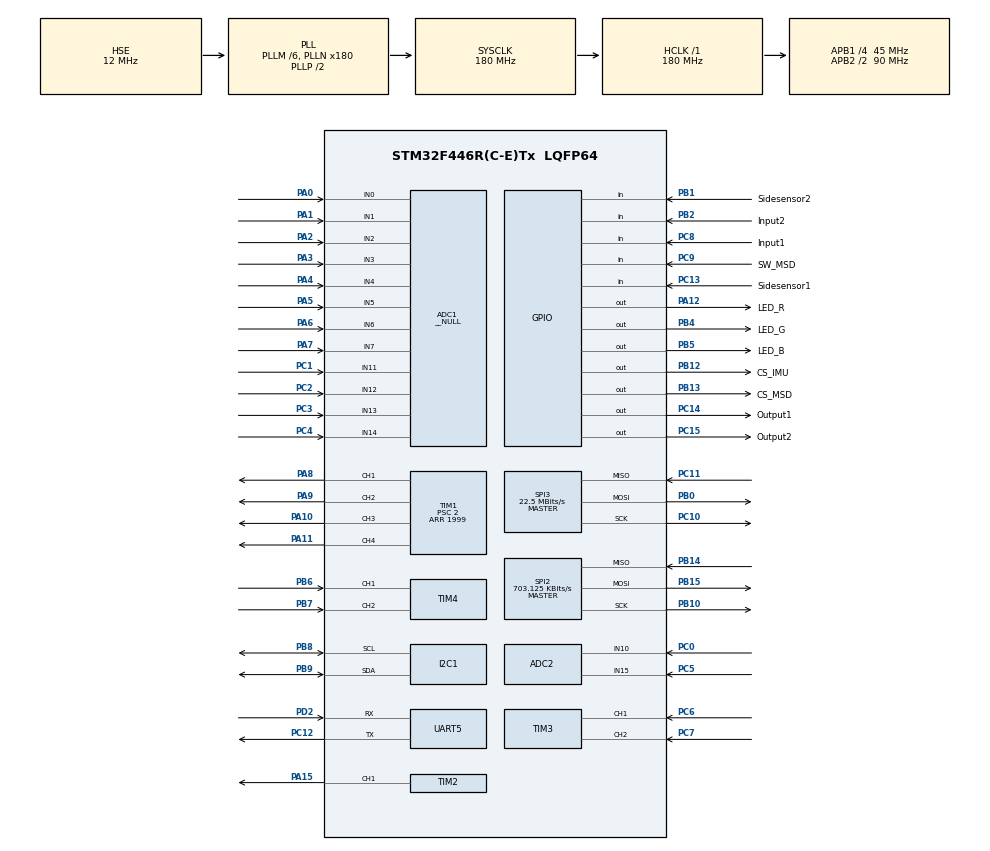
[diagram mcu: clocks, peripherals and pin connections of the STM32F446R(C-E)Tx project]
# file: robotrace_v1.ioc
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ADC1.Channel-1\#ChannelRegularConversion=ADC_CHANNEL_11
ADC1.Channel-10\#ChannelRegularConversion=ADC_CHANNEL_6
ADC1.Channel-11\#ChannelRegularConversion=ADC_CHANNEL_7
ADC1.Channel-12\#ChannelRegularConversion=ADC_CHANNEL_14
ADC1.Channel-2\#ChannelRegularConversion=ADC_CHANNEL_12
ADC1.Channel-3\#ChannelRegularConversion=ADC_CHANNEL_13
ADC1.Channel-4\#ChannelRegularConversion=ADC_CHANNEL_0
ADC1.Channel-5\#ChannelRegularConversion=ADC_CHANNEL_1
ADC1.Channel-6\#ChannelRegularConversion=ADC_CHANNEL_2
ADC1.Channel-7\#ChannelRegularConversion=ADC_CHANNEL_3
ADC1.Channel-8\#ChannelRegularConversion=ADC_CHANNEL_4
ADC1.Channel-9\#ChannelRegularConversion=ADC_CHANNEL_5
ADC1.ClockPrescaler=ADC_CLOCK_SYNC_PCLK_DIV4
ADC1.ContinuousConvMode=DISABLE
ADC1.DMAContinuousRequests=ENABLE
ADC1.DiscontinuousConvMode=DISABLE
ADC1.EOCSelection=ADC_EOC_SINGLE_CONV
ADC1.ExternalTrigConv=ADC_EXTERNALTRIGCONV_T2_TRGO
ADC1.ExternalTrigConvEdge=ADC_EXTERNALTRIGCONVEDGE_RISING
ADC1.InjNumberOfConversion=0
ADC1.Mode=__NULL
ADC1.NbrOfConversion=12
ADC1.NbrOfConversionFlag=1
ADC1.Rank-1\#ChannelRegularConversion=1
ADC1.Rank-10\#ChannelRegularConversion=10
ADC1.Rank-11\#ChannelRegularConversion=11
ADC1.Rank-12\#ChannelRegularConversion=12
ADC1.Rank-2\#ChannelRegularConversion=2
ADC1.Rank-3\#ChannelRegularConversion=3
ADC1.Rank-4\#ChannelRegularConversion=4
ADC1.Rank-5\#ChannelRegularConversion=5
ADC1.Rank-6\#ChannelRegularConversion=6
ADC1.Rank-7\#ChannelRegularConversion=7
ADC1.Rank-8\#ChannelRegularConversion=8
ADC1.Rank-9\#ChannelRegularConversion=9
ADC1.SamplingTime-1\#ChannelRegularConversion=ADC_SAMPLETIME_84CYCLES
ADC1.SamplingTime-10\#ChannelRegularConversion=ADC_SAMPLETIME_84CYCLES
ADC1.SamplingTime-11\#ChannelRegularConversion=ADC_SAMPLETIME_84CYCLES
ADC1.SamplingTime-12\#ChannelRegularConversion=ADC_SAMPLETIME_84CYCLES
ADC1.SamplingTime-2\#ChannelRegularConversion=ADC_SAMPLETIME_84CYCLES
ADC1.SamplingTime-3\#ChannelRegularConversion=ADC_SAMPLETIME_84CYCLES
ADC1.SamplingTime-4\#ChannelRegularConversion=ADC_SAMPLETIME_84CYCLES
ADC1.SamplingTime-5\#ChannelRegularConversion=ADC_SAMPLETIME_84CYCLES
ADC1.SamplingTime-6\#ChannelRegularConversion=ADC_SAMPLETIME_84CYCLES
ADC1.SamplingTime-7\#ChannelRegularConversion=ADC_SAMPLETIME_84CYCLES
ADC1.SamplingTime-8\#ChannelRegularConversion=ADC_SAMPLETIME_84CYCLES
ADC1.SamplingTime-9\#ChannelRegularConversion=ADC_SAMPLETIME_84CYCLES
ADC1.ScanConvMode=ENABLE
ADC1.master=1
ADC2.Channel-0\#ChannelRegularConversion=ADC_CHANNEL_10
ADC2.Channel-1\#ChannelRegularConversion=ADC_CHANNEL_15
ADC2.ContinuousConvMode=ENABLE
ADC2.EOCSelection=ADC_EOC_SINGLE_CONV
ADC2.NbrOfConversion=2
ADC2.NbrOfConversionFlag=1
ADC2.Rank-0\#ChannelRegularConversion=1
ADC2.Rank-1\#ChannelRegularConversion=2
ADC2.SamplingTime-0\#ChannelRegularConversion=ADC_SAMPLETIME_480CYCLES
ADC2.SamplingTime-1\#ChannelRegularConversion=ADC_SAMPLETIME_480CYCLES
ADC2.ScanConvMode=ENABLE
Dma.ADC1.0.Direction=DMA_PERIPH_TO_MEMORY
Dma.ADC1.0.FIFOMode=DMA_FIFOMODE_DISABLE
Dma.ADC1.0.Instance=DMA2_Stream0
Dma.ADC1.0.MemDataAlignment=DMA_MDATAALIGN_HALFWORD
Dma.ADC1.0.MemInc=DMA_MINC_ENABLE
Dma.ADC1.0.Mode=DMA_CIRCULAR
Dma.ADC1.0.PeriphDataAlignment=DMA_PDATAALIGN_HALFWORD
Dma.ADC1.0.PeriphInc=DMA_PINC_DISABLE
Dma.ADC1.0.Priority=DMA_PRIORITY_LOW
Dma.Request0=ADC1
I2C1.DutyCycle=I2C_DUTYCYCLE_2
I2C1.I2C_Mode=I2C_Fast
I2C1.NoStretchMode=I2C_NOSTRETCH_ENABLE
Mcu.Family=STM32F4
Mcu.Name=STM32F446R(C-E)Tx
Mcu.Package=LQFP64
NVIC.DMA2_Stream0_IRQn=true\:0\:0\:false\:false\:true\:false\:true\:true
NVIC.PriorityGroup=NVIC_PRIORITYGROUP_0
NVIC.TIM2_IRQn=true\:0\:0\:false\:false\:true\:true\:true\:true
NVIC.TIM6_DAC_IRQn=true\:0\:0\:false\:false\:true\:true\:true\:true
NVIC.TIM7_IRQn=true\:0\:0\:false\:false\:true\:true\:true\:true
PA0-WKUP.Signal=ADCx_IN0
PA1.Signal=ADCx_IN1
PA10.Signal=S_TIM1_CH3
PA11.Signal=S_TIM1_CH4
PA12.GPIO_Label=LED_R
PA12.GPIO_PuPd=GPIO_PULLUP
PA12.PinState=GPIO_PIN_SET
PA12.Signal=GPIO_Output
PA13.GPIO_Label=TMS
PA13.Mode=Trace_Asynchronous_SW
PA13.Signal=SYS_JTMS-SWDIO
PA14.GPIO_Label=TCK
PA14.Mode=Trace_Asynchronous_SW
PA14.Signal=SYS_JTCK-SWCLK
PA15.Signal=S_TIM2_CH1_ETR
PA2.Signal=ADCx_IN2
PA3.Signal=ADCx_IN3
PA4.Signal=ADCx_IN4
PA5.Signal=ADCx_IN5
PA6.Signal=ADCx_IN6
PA7.Signal=ADCx_IN7
PA8.Signal=S_TIM1_CH1
PA9.Signal=S_TIM1_CH2
PB0.Mode=Full_Duplex_Master
PB0.Signal=SPI3_MOSI
PB1.GPIO_Label=Sidesensor2
PB1.GPIO_PuPd=GPIO_PULLUP
PB1.Signal=GPIO_Input
PB10.Mode=Full_Duplex_Master
PB10.Signal=SPI2_SCK
PB12.GPIO_Label=CS_IMU
PB12.GPIO_PuPd=GPIO_PULLUP
PB12.PinState=GPIO_PIN_SET
PB12.Signal=GPIO_Output
PB13.GPIO_Label=CS_MSD
PB13.GPIO_PuPd=GPIO_PULLUP
PB13.PinState=GPIO_PIN_SET
PB13.Signal=GPIO_Output
PB14.Mode=Full_Duplex_Master
PB14.Signal=SPI2_MISO
PB15.Mode=Full_Duplex_Master
PB15.Signal=SPI2_MOSI
PB2.GPIO_Label=Input2
PB2.Signal=GPIO_Input
PB3.GPIO_Label=SWO
PB3.Mode=Trace_Asynchronous_SW
PB3.Signal=SYS_JTDO-SWO
PB4.GPIO_Label=LED_G
PB4.GPIO_PuPd=GPIO_PULLUP
PB4.PinState=GPIO_PIN_SET
PB4.Signal=GPIO_Output
PB5.GPIO_Label=LED_B
PB5.GPIO_PuPd=GPIO_PULLUP
PB5.PinState=GPIO_PIN_SET
PB5.Signal=GPIO_Output
PB6.Signal=S_TIM4_CH1
PB7.Signal=S_TIM4_CH2
PB8.Mode=I2C
PB8.Signal=I2C1_SCL
PB9.Mode=I2C
PB9.Signal=I2C1_SDA
PC0.Signal=ADCx_IN10
PC1.Signal=ADCx_IN11
PC10.Mode=Full_Duplex_Master
PC10.Signal=SPI3_SCK
PC11.Mode=Full_Duplex_Master
PC11.Signal=SPI3_MISO
PC12.Mode=Asynchronous
PC12.Signal=UART5_TX
PC13.GPIO_Label=Sidesensor1
PC13.GPIO_PuPd=GPIO_PULLUP
PC13.Signal=GPIO_Input
PC14-OSC32_IN.GPIO_Label=Output1
PC14-OSC32_IN.GPIO_PuPd=GPIO_PULLUP
PC14-OSC32_IN.Signal=GPIO_Output
PC15-OSC32_OUT.GPIO_Label=Output2
PC15-OSC32_OUT.GPIO_PuPd=GPIO_PULLUP
PC15-OSC32_OUT.Signal=GPIO_Output
PC2.Signal=ADCx_IN12
PC3.Signal=ADCx_IN13
PC4.Signal=ADCx_IN14
PC5.Signal=ADCx_IN15
PC6.Signal=S_TIM3_CH1
PC7.Signal=S_TIM3_CH2
PC8.GPIO_Label=Input1
PC8.GPIO_PuPd=GPIO_PULLUP
PC8.Signal=GPIO_Input
PC9.GPIO_Label=SW_MSD
PC9.GPIO_PuPd=GPIO_PULLUP
PC9.Signal=GPIO_Input
PD2.Mode=Asynchronous
PD2.Signal=UART5_RX
PH0-OSC_IN.Mode=HSE-External-Oscillator
PH0-OSC_IN.Signal=RCC_OSC_IN
PH1-OSC_OUT.Mode=HSE-External-Oscillator
PH1-OSC_OUT.Signal=RCC_OSC_OUT
ProjectManager.HeapSize=0x400
ProjectManager.StackSize=0x800
ProjectManager.TargetToolchain=STM32CubeIDE
RCC.48MHZClocksFreq_Value=84000000
RCC.AHBFreq_Value=180000000
RCC.APB1CLKDivider=RCC_HCLK_DIV4
RCC.APB1Freq_Value=45000000
RCC.APB1TimFreq_Value=90000000
RCC.APB2CLKDivider=RCC_HCLK_DIV2
RCC.APB2Freq_Value=90000000
RCC.APB2TimFreq_Value=180000000
RCC.CortexFreq_Value=180000000
RCC.FLatency-AdvancedSettings=FLASH_LATENCY_5
RCC.HCLKFreq_Value=180000000
RCC.HSE_VALUE=12000000
RCC.HSI_VALUE=16000000
RCC.PLLM=6
RCC.PLLN=180
RCC.PLLSourceVirtual=RCC_PLLSOURCE_HSE
RCC.SYSCLKFreq_VALUE=180000000
RCC.SYSCLKSource=RCC_SYSCLKSOURCE_PLLCLK
RCC.USBFreq_Value=180000000
RCC.VCOOutputFreq_Value=360000000
SH.ADCx_IN0.0=ADC1_IN0,IN0
SH.ADCx_IN1.0=ADC1_IN1,IN1
SH.ADCx_IN10.0=ADC2_IN10,IN10
SH.ADCx_IN11.0=ADC1_IN11,IN11
SH.ADCx_IN12.0=ADC1_IN12,IN12
SH.ADCx_IN13.0=ADC1_IN13,IN13
SH.ADCx_IN14.0=ADC1_IN14,IN14
SH.ADCx_IN15.0=ADC2_IN15,IN15
SH.ADCx_IN2.0=ADC1_IN2,IN2
SH.ADCx_IN3.0=ADC1_IN3,IN3
SH.ADCx_IN4.0=ADC1_IN4,IN4
SH.ADCx_IN5.0=ADC1_IN5,IN5
SH.ADCx_IN6.0=ADC1_IN6,IN6
SH.ADCx_IN7.0=ADC1_IN7,IN7
SH.S_TIM1_CH1.0=TIM1_CH1,PWM Generation1 CH1
SH.S_TIM1_CH2.0=TIM1_CH2,PWM Generation2 CH2
SH.S_TIM1_CH3.0=TIM1_CH3,PWM Generation3 CH3
SH.S_TIM1_CH4.0=TIM1_CH4,PWM Generation4 CH4
SH.S_TIM2_CH1_ETR.0=TIM2_CH1,PWM Generation1 CH1
SH.S_TIM3_CH1.0=TIM3_CH1,Encoder_Interface
SH.S_TIM3_CH2.0=TIM3_CH2,Encoder_Interface
SH.S_TIM4_CH1.0=TIM4_CH1,Encoder_Interface
SH.S_TIM4_CH2.0=TIM4_CH2,Encoder_Interface
SPI2.BaudRatePrescaler=SPI_BAUDRATEPRESCALER_64
SPI2.CLKPhase=SPI_PHASE_2EDGE
SPI2.CLKPolarity=SPI_POLARITY_HIGH
SPI2.CalculateBaudRate=703.125 KBits/s
SPI2.Direction=SPI_DIRECTION_2LINES
SPI2.FirstBit=SPI_FIRSTBIT_MSB
SPI2.Mode=SPI_MODE_MASTER
SPI2.VirtualType=VM_MASTER
SPI3.BaudRatePrescaler=SPI_BAUDRATEPRESCALER_2
SPI3.CalculateBaudRate=22.5 MBits/s
SPI3.Direction=SPI_DIRECTION_2LINES
SPI3.Mode=SPI_MODE_MASTER
SPI3.VirtualType=VM_MASTER
TIM1.Channel-PWM\ Generation1\ CH1=TIM_CHANNEL_1
TIM1.Channel-PWM\ Generation2\ CH2=TIM_CHANNEL_2
TIM1.Channel-PWM\ Generation3\ CH3=TIM_CHANNEL_3
TIM1.Channel-PWM\ Generation4\ CH4=TIM_CHANNEL_4
TIM1.OC3Preload_PWM=DISABLE
TIM1.OC4Preload_PWM=DISABLE
TIM1.Period=1999
TIM1.Prescaler=2
TIM2.AutoReloadPreload=TIM_AUTORELOAD_PRELOAD_DISABLE
TIM2.Channel-PWM\ Generation1\ CH1=TIM_CHANNEL_1
TIM2.CounterMode=TIM_COUNTERMODE_UP
TIM2.Period=1124
TIM2.Prescaler=11
TIM2.TIM_MasterOutputTrigger=TIM_TRGO_UPDATE
TIM3.EncoderMode=TIM_ENCODERMODE_TI12
TIM3.IC1Polarity=TIM_ICPOLARITY_RISING
TIM3.IC2Polarity=TIM_ICPOLARITY_FALLING
TIM4.EncoderMode=TIM_ENCODERMODE_TI12
TIM4.IC2Polarity=TIM_ICPOLARITY_RISING
TIM6.Period=7499
TIM6.Prescaler=11
TIM7.Period=749
TIM7.Prescaler=11
UART5.VirtualMode=Asynchronous
VP_FATFS_VS_Generic.Mode=User_defined
VP_TIM6_VS_ClockSourceINT.Mode=Enable_Timer
VP_TIM7_VS_ClockSourceINT.Mode=Enable_Timer
board=NUCLEO-F446RE

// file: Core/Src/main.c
/* USER CODE BEGIN Header */
/**
  ******************************************************************************
  * @file           : main.c
  * @brief          : Main program body
  ******************************************************************************
  * @attention
  *
  * Copyright (c) 2022 STMicroelectronics.
  * All rights reserved.
  *
  * This software is licensed under terms that can be found in the LICENSE file
  * in the root directory of this software component.
  * If no LICENSE file comes with this software, it is provided AS-IS.
  *
  ******************************************************************************
  */
/* USER CODE END Header */
#include "main.h"
#include "fatfs.h"

ADC_HandleTypeDef hadc1;
ADC_HandleTypeDef hadc2;
DMA_HandleTypeDef hdma_adc1;

I2C_HandleTypeDef hi2c1;

SPI_HandleTypeDef hspi2;
SPI_HandleTypeDef hspi3;

TIM_HandleTypeDef htim1;
TIM_HandleTypeDef htim2;
TIM_HandleTypeDef htim3;
TIM_HandleTypeDef htim4;
TIM_HandleTypeDef htim6;
TIM_HandleTypeDef htim7;

UART_HandleTypeDef huart5;

void SystemClock_Config(void);
static void MX_GPIO_Init(void);
static void MX_DMA_Init(void);
static void MX_ADC1_Init(void);
static void MX_I2C1_Init(void);
static void MX_SPI2_Init(void);
static void MX_TIM1_Init(void);
static void MX_TIM2_Init(void);
static void MX_UART5_Init(void);
static void MX_TIM3_Init(void);
static void MX_TIM4_Init(void);
static void MX_SPI3_Init(void);
static void MX_TIM6_Init(void);
static void MX_ADC2_Init(void);
static void MX_TIM7_Init(void);

int main(void)
{

  /* MCU Configuration--------------------------------------------------------*/

  /* Reset of all peripherals, Initializes the Flash interface and the Systick. */
  HAL_Init();

  /* Configure the system clock */
  SystemClock_Config();

  /* Initialize all configured peripherals */
  MX_GPIO_Init();
  MX_DMA_Init();
  MX_ADC1_Init();
  MX_I2C1_Init();
  MX_SPI2_Init();
  MX_TIM1_Init();
  MX_TIM2_Init();
  MX_UART5_Init();
  MX_TIM3_Init();
  MX_TIM4_Init();
  MX_SPI3_Init();
  MX_TIM6_Init();
  MX_ADC2_Init();
  MX_FATFS_Init();
  MX_TIM7_Init();
  /* USER CODE BEGIN 2 */
  initSystem();

  /* USER CODE END 2 */

  /* Infinite loop */
  /* USER CODE BEGIN WHILE */
  while (1)
  {
    loopSystem();
    /* USER CODE END WHILE */

  }
}

void SystemClock_Config(void)
{
  RCC_OscInitTypeDef RCC_OscInitStruct = {0};
  RCC_ClkInitTypeDef RCC_ClkInitStruct = {0};

  /** Configure the main internal regulator output voltage
  */
  __HAL_RCC_PWR_CLK_ENABLE();
  __HAL_PWR_VOLTAGESCALING_CONFIG(PWR_REGULATOR_VOLTAGE_SCALE1);

  /** Initializes the RCC Oscillators according to the specified parameters
  * in the RCC_OscInitTypeDef structure.
  */
  RCC_OscInitStruct.OscillatorType = RCC_OSCILLATORTYPE_HSE;
  RCC_OscInitStruct.HSEState = RCC_HSE_ON;
  RCC_OscInitStruct.PLL.PLLState = RCC_PLL_ON;
  RCC_OscInitStruct.PLL.PLLSource = RCC_PLLSOURCE_HSE;
  RCC_OscInitStruct.PLL.PLLM = 6;
  RCC_OscInitStruct.PLL.PLLN = 180;
  RCC_OscInitStruct.PLL.PLLP = RCC_PLLP_DIV2;
  RCC_OscInitStruct.PLL.PLLQ = 2;
  RCC_OscInitStruct.PLL.PLLR = 2;
  if (HAL_RCC_OscConfig(&RCC_OscInitStruct) != HAL_OK)
  {
    Error_Handler();
  }

  /** Activate the Over-Drive mode
  */
  if (HAL_PWREx_EnableOverDrive() != HAL_OK)
  {
    Error_Handler();
  }

  /** Initializes the CPU, AHB and APB buses clocks
  */
  RCC_ClkInitStruct.ClockType = RCC_CLOCKTYPE_HCLK|RCC_CLOCKTYPE_SYSCLK
                              |RCC_CLOCKTYPE_PCLK1|RCC_CLOCKTYPE_PCLK2;
  RCC_ClkInitStruct.SYSCLKSource = RCC_SYSCLKSOURCE_PLLCLK;
  RCC_ClkInitStruct.AHBCLKDivider = RCC_SYSCLK_DIV1;
  RCC_ClkInitStruct.APB1CLKDivider = RCC_HCLK_DIV4;
  RCC_ClkInitStruct.APB2CLKDivider = RCC_HCLK_DIV2;

  if (HAL_RCC_ClockConfig(&RCC_ClkInitStruct, FLASH_LATENCY_5) != HAL_OK)
  {
    Error_Handler();
  }
}

static void MX_ADC1_Init(void)
{

  ADC_ChannelConfTypeDef sConfig = {0};

  /** Configure the global features of the ADC (Clock, Resolution, Data Alignment and number of conversion)
  */
  hadc1.Instance = ADC1;
  hadc1.Init.ClockPrescaler = ADC_CLOCK_SYNC_PCLK_DIV4;
  hadc1.Init.Resolution = ADC_RESOLUTION_12B;
  hadc1.Init.ScanConvMode = ENABLE;
  hadc1.Init.ContinuousConvMode = DISABLE;
  hadc1.Init.DiscontinuousConvMode = DISABLE;
  hadc1.Init.ExternalTrigConvEdge = ADC_EXTERNALTRIGCONVEDGE_RISING;
  hadc1.Init.ExternalTrigConv = ADC_EXTERNALTRIGCONV_T2_TRGO;
  hadc1.Init.DataAlign = ADC_DATAALIGN_RIGHT;
  hadc1.Init.NbrOfConversion = 12;
  hadc1.Init.DMAContinuousRequests = ENABLE;
  hadc1.Init.EOCSelection = ADC_EOC_SINGLE_CONV;
  if (HAL_ADC_Init(&hadc1) != HAL_OK)
  {
    Error_Handler();
  }

  /** Configure for the selected ADC regular channel its corresponding rank in the sequencer and its sample time.
  */
  sConfig.Channel = ADC_CHANNEL_11;
  sConfig.Rank = 1;
  sConfig.SamplingTime = ADC_SAMPLETIME_84CYCLES;
  if (HAL_ADC_ConfigChannel(&hadc1, &sConfig) != HAL_OK)
  {
    Error_Handler();
  }

  /** Configure for the selected ADC regular channel its corresponding rank in the sequencer and its sample time.
  */
  sConfig.Channel = ADC_CHANNEL_12;
  sConfig.Rank = 2;
  if (HAL_ADC_ConfigChannel(&hadc1, &sConfig) != HAL_OK)
  {
    Error_Handler();
  }

  /** Configure for the selected ADC regular channel its corresponding rank in the sequencer and its sample time.
  */
  sConfig.Channel = ADC_CHANNEL_13;
  sConfig.Rank = 3;
  if (HAL_ADC_ConfigChannel(&hadc1, &sConfig) != HAL_OK)
  {
    Error_Handler();
  }

  /** Configure for the selected ADC regular channel its corresponding rank in the sequencer and its sample time.
  */
  sConfig.Channel = ADC_CHANNEL_0;
  sConfig.Rank = 4;
  if (HAL_ADC_ConfigChannel(&hadc1, &sConfig) != HAL_OK)
  {
    Error_Handler();
  }

  /** Configure for the selected ADC regular channel its corresponding rank in the sequencer and its sample time.
  */
  sConfig.Channel = ADC_CHANNEL_1;
  sConfig.Rank = 5;
  if (HAL_ADC_ConfigChannel(&hadc1, &sConfig) != HAL_OK)
  {
    Error_Handler();
  }

  /** Configure for the selected ADC regular channel its corresponding rank in the sequencer and its sample time.
  */
  sConfig.Channel = ADC_CHANNEL_2;
  sConfig.Rank = 6;
  if (HAL_ADC_ConfigChannel(&hadc1, &sConfig) != HAL_OK)
  {
    Error_Handler();
  }

  /** Configure for the selected ADC regular channel its corresponding rank in the sequencer and its sample time.
  */
  sConfig.Channel = ADC_CHANNEL_3;
  sConfig.Rank = 7;
  if (HAL_ADC_ConfigChannel(&hadc1, &sConfig) != HAL_OK)
  {
    Error_Handler();
  }

  /** Configure for the selected ADC regular channel its corresponding rank in the sequencer and its sample time.
  */
  sConfig.Channel = ADC_CHANNEL_4;
  sConfig.Rank = 8;
  if (HAL_ADC_ConfigChannel(&hadc1, &sConfig) != HAL_OK)
  {
    Error_Handler();
  }

  /** Configure for the selected ADC regular channel its corresponding rank in the sequencer and its sample time.
  */
  sConfig.Channel = ADC_CHANNEL_5;
  sConfig.Rank = 9;
  if (HAL_ADC_ConfigChannel(&hadc1, &sConfig) != HAL_OK)
  {
    Error_Handler();
  }

  /** Configure for the selected ADC regular channel its corresponding rank in the sequencer and its sample time.
  */
  sConfig.Channel = ADC_CHANNEL_6;
  sConfig.Rank = 10;
  if (HAL_ADC_ConfigChannel(&hadc1, &sConfig) != HAL_OK)
  {
    Error_Handler();
  }

  /** Configure for the selected ADC regular channel its corresponding rank in the sequencer and its sample time.
  */
  sConfig.Channel = ADC_CHANNEL_7;
  sConfig.Rank = 11;
  if (HAL_ADC_ConfigChannel(&hadc1, &sConfig) != HAL_OK)
  {
    Error_Handler();
  }

  /** Configure for the selected ADC regular channel its corresponding rank in the sequencer and its sample time.
  */
  sConfig.Channel = ADC_CHANNEL_14;
  sConfig.Rank = 12;
  if (HAL_ADC_ConfigChannel(&hadc1, &sConfig) != HAL_OK)
  {
    Error_Handler();
  }

}

static void MX_ADC2_Init(void)
{

  ADC_ChannelConfTypeDef sConfig = {0};

  /** Configure the global features of the ADC (Clock, Resolution, Data Alignment and number of conversion)
  */
  hadc2.Instance = ADC2;
  hadc2.Init.ClockPrescaler = ADC_CLOCK_SYNC_PCLK_DIV4;
  hadc2.Init.Resolution = ADC_RESOLUTION_12B;
  hadc2.Init.ScanConvMode = ENABLE;
  hadc2.Init.ContinuousConvMode = ENABLE;
  hadc2.Init.DiscontinuousConvMode = DISABLE;
  hadc2.Init.ExternalTrigConvEdge = ADC_EXTERNALTRIGCONVEDGE_NONE;
  hadc2.Init.ExternalTrigConv = ADC_SOFTWARE_START;
  hadc2.Init.DataAlign = ADC_DATAALIGN_RIGHT;
  hadc2.Init.NbrOfConversion = 2;
  hadc2.Init.DMAContinuousRequests = DISABLE;
  hadc2.Init.EOCSelection = ADC_EOC_SINGLE_CONV;
  if (HAL_ADC_Init(&hadc2) != HAL_OK)
  {
    Error_Handler();
  }

  /** Configure for the selected ADC regular channel its corresponding rank in the sequencer and its sample time.
  */
  sConfig.Channel = ADC_CHANNEL_10;
  sConfig.Rank = 1;
  sConfig.SamplingTime = ADC_SAMPLETIME_480CYCLES;
  if (HAL_ADC_ConfigChannel(&hadc2, &sConfig) != HAL_OK)
  {
    Error_Handler();
  }

  /** Configure for the selected ADC regular channel its corresponding rank in the sequencer and its sample time.
  */
  sConfig.Channel = ADC_CHANNEL_15;
  sConfig.Rank = 2;
  if (HAL_ADC_ConfigChannel(&hadc2, &sConfig) != HAL_OK)
  {
    Error_Handler();
  }

}

static void MX_I2C1_Init(void)
{

  hi2c1.Instance = I2C1;
  hi2c1.Init.ClockSpeed = 400000;
  hi2c1.Init.DutyCycle = I2C_DUTYCYCLE_2;
  hi2c1.Init.OwnAddress1 = 0;
  hi2c1.Init.AddressingMode = I2C_ADDRESSINGMODE_7BIT;
  hi2c1.Init.DualAddressMode = I2C_DUALADDRESS_DISABLE;
  hi2c1.Init.OwnAddress2 = 0;
  hi2c1.Init.GeneralCallMode = I2C_GENERALCALL_DISABLE;
  hi2c1.Init.NoStretchMode = I2C_NOSTRETCH_ENABLE;
  if (HAL_I2C_Init(&hi2c1) != HAL_OK)
  {
    Error_Handler();
  }

}

static void MX_SPI2_Init(void)
{

  /* SPI2 parameter configuration*/
  hspi2.Instance = SPI2;
  hspi2.Init.Mode = SPI_MODE_MASTER;
  hspi2.Init.Direction = SPI_DIRECTION_2LINES;
  hspi2.Init.DataSize = SPI_DATASIZE_8BIT;
  hspi2.Init.CLKPolarity = SPI_POLARITY_HIGH;
  hspi2.Init.CLKPhase = SPI_PHASE_2EDGE;
  hspi2.Init.NSS = SPI_NSS_SOFT;
  hspi2.Init.BaudRatePrescaler = SPI_BAUDRATEPRESCALER_64;
  hspi2.Init.FirstBit = SPI_FIRSTBIT_MSB;
  hspi2.Init.TIMode = SPI_TIMODE_DISABLE;
  hspi2.Init.CRCCalculation = SPI_CRCCALCULATION_DISABLE;
  hspi2.Init.CRCPolynomial = 10;
  if (HAL_SPI_Init(&hspi2) != HAL_OK)
  {
    Error_Handler();
  }

}

static void MX_SPI3_Init(void)
{

  /* SPI3 parameter configuration*/
  hspi3.Instance = SPI3;
  hspi3.Init.Mode = SPI_MODE_MASTER;
  hspi3.Init.Direction = SPI_DIRECTION_2LINES;
  hspi3.Init.DataSize = SPI_DATASIZE_8BIT;
  hspi3.Init.CLKPolarity = SPI_POLARITY_LOW;
  hspi3.Init.CLKPhase = SPI_PHASE_1EDGE;
  hspi3.Init.NSS = SPI_NSS_SOFT;
  hspi3.Init.BaudRatePrescaler = SPI_BAUDRATEPRESCALER_2;
  hspi3.Init.FirstBit = SPI_FIRSTBIT_MSB;
  hspi3.Init.TIMode = SPI_TIMODE_DISABLE;
  hspi3.Init.CRCCalculation = SPI_CRCCALCULATION_DISABLE;
  hspi3.Init.CRCPolynomial = 10;
  if (HAL_SPI_Init(&hspi3) != HAL_OK)
  {
    Error_Handler();
  }

}

static void MX_TIM1_Init(void)
{

  TIM_MasterConfigTypeDef sMasterConfig = {0};
  TIM_OC_InitTypeDef sConfigOC = {0};
  TIM_BreakDeadTimeConfigTypeDef sBreakDeadTimeConfig = {0};

  htim1.Instance = TIM1;
  htim1.Init.Prescaler = 2;
  htim1.Init.CounterMode = TIM_COUNTERMODE_UP;
  htim1.Init.Period = 1999;
  htim1.Init.ClockDivision = TIM_CLOCKDIVISION_DIV1;
  htim1.Init.RepetitionCounter = 0;
  htim1.Init.AutoReloadPreload = TIM_AUTORELOAD_PRELOAD_DISABLE;
  if (HAL_TIM_PWM_Init(&htim1) != HAL_OK)
  {
    Error_Handler();
  }
  sMasterConfig.MasterOutputTrigger = TIM_TRGO_RESET;
  sMasterConfig.MasterSlaveMode = TIM_MASTERSLAVEMODE_DISABLE;
  if (HAL_TIMEx_MasterConfigSynchronization(&htim1, &sMasterConfig) != HAL_OK)
  {
    Error_Handler();
  }
  sConfigOC.OCMode = TIM_OCMODE_PWM1;
  sConfigOC.Pulse = 0;
  sConfigOC.OCPolarity = TIM_OCPOLARITY_HIGH;
  sConfigOC.OCNPolarity = TIM_OCNPOLARITY_HIGH;
  sConfigOC.OCFastMode = TIM_OCFAST_DISABLE;
  sConfigOC.OCIdleState = TIM_OCIDLESTATE_RESET;
  sConfigOC.OCNIdleState = TIM_OCNIDLESTATE_RESET;
  if (HAL_TIM_PWM_ConfigChannel(&htim1, &sConfigOC, TIM_CHANNEL_1) != HAL_OK)
  {
    Error_Handler();
  }
  if (HAL_TIM_PWM_ConfigChannel(&htim1, &sConfigOC, TIM_CHANNEL_2) != HAL_OK)
  {
    Error_Handler();
  }
  if (HAL_TIM_PWM_ConfigChannel(&htim1, &sConfigOC, TIM_CHANNEL_3) != HAL_OK)
  {
    Error_Handler();
  }
  __HAL_TIM_DISABLE_OCxPRELOAD(&htim1, TIM_CHANNEL_3);
  if (HAL_TIM_PWM_ConfigChannel(&htim1, &sConfigOC, TIM_CHANNEL_4) != HAL_OK)
  {
    Error_Handler();
  }
  __HAL_TIM_DISABLE_OCxPRELOAD(&htim1, TIM_CHANNEL_4);
  sBreakDeadTimeConfig.OffStateRunMode = TIM_OSSR_DISABLE;
  sBreakDeadTimeConfig.OffStateIDLEMode = TIM_OSSI_DISABLE;
  sBreakDeadTimeConfig.LockLevel = TIM_LOCKLEVEL_OFF;
  sBreakDeadTimeConfig.DeadTime = 0;
  sBreakDeadTimeConfig.BreakState = TIM_BREAK_DISABLE;
  sBreakDeadTimeConfig.BreakPolarity = TIM_BREAKPOLARITY_HIGH;
  sBreakDeadTimeConfig.AutomaticOutput = TIM_AUTOMATICOUTPUT_DISABLE;
  if (HAL_TIMEx_ConfigBreakDeadTime(&htim1, &sBreakDeadTimeConfig) != HAL_OK)
  {
    Error_Handler();
  }
  HAL_TIM_MspPostInit(&htim1);

}

static void MX_TIM2_Init(void)
{

  TIM_MasterConfigTypeDef sMasterConfig = {0};
  TIM_OC_InitTypeDef sConfigOC = {0};

  htim2.Instance = TIM2;
  htim2.Init.Prescaler = 11;
  htim2.Init.CounterMode = TIM_COUNTERMODE_UP;
  htim2.Init.Period = 1124;
  htim2.Init.ClockDivision = TIM_CLOCKDIVISION_DIV1;
  htim2.Init.AutoReloadPreload = TIM_AUTORELOAD_PRELOAD_DISABLE;
  if (HAL_TIM_PWM_Init(&htim2) != HAL_OK)
  {
    Error_Handler();
  }
  sMasterConfig.MasterOutputTrigger = TIM_TRGO_UPDATE;
  sMasterConfig.MasterSlaveMode = TIM_MASTERSLAVEMODE_DISABLE;
  if (HAL_TIMEx_MasterConfigSynchronization(&htim2, &sMasterConfig) != HAL_OK)
  {
    Error_Handler();
  }
  sConfigOC.OCMode = TIM_OCMODE_PWM1;
  sConfigOC.Pulse = 0;
  sConfigOC.OCPolarity = TIM_OCPOLARITY_HIGH;
  sConfigOC.OCFastMode = TIM_OCFAST_DISABLE;
  if (HAL_TIM_PWM_ConfigChannel(&htim2, &sConfigOC, TIM_CHANNEL_1) != HAL_OK)
  {
    Error_Handler();
  }
  HAL_TIM_MspPostInit(&htim2);

}

static void MX_TIM3_Init(void)
{

  TIM_Encoder_InitTypeDef sConfig = {0};
  TIM_MasterConfigTypeDef sMasterConfig = {0};

  htim3.Instance = TIM3;
  htim3.Init.Prescaler = 0;
  htim3.Init.CounterMode = TIM_COUNTERMODE_UP;
  htim3.Init.Period = 65535;
  htim3.Init.ClockDivision = TIM_CLOCKDIVISION_DIV1;
  htim3.Init.AutoReloadPreload = TIM_AUTORELOAD_PRELOAD_DISABLE;
  sConfig.EncoderMode = TIM_ENCODERMODE_TI12;
  sConfig.IC1Polarity = TIM_ICPOLARITY_RISING;
  sConfig.IC1Selection = TIM_ICSELECTION_DIRECTTI;
  sConfig.IC1Prescaler = TIM_ICPSC_DIV1;
  sConfig.IC1Filter = 0;
  sConfig.IC2Polarity = TIM_ICPOLARITY_FALLING;
  sConfig.IC2Selection = TIM_ICSELECTION_DIRECTTI;
  sConfig.IC2Prescaler = TIM_ICPSC_DIV1;
  sConfig.IC2Filter = 0;
  if (HAL_TIM_Encoder_Init(&htim3, &sConfig) != HAL_OK)
  {
    Error_Handler();
  }
  sMasterConfig.MasterOutputTrigger = TIM_TRGO_RESET;
  sMasterConfig.MasterSlaveMode = TIM_MASTERSLAVEMODE_DISABLE;
  if (HAL_TIMEx_MasterConfigSynchronization(&htim3, &sMasterConfig) != HAL_OK)
  {
    Error_Handler();
  }

}

static void MX_TIM4_Init(void)
{

  TIM_Encoder_InitTypeDef sConfig = {0};
  TIM_MasterConfigTypeDef sMasterConfig = {0};

  htim4.Instance = TIM4;
  htim4.Init.Prescaler = 0;
  htim4.Init.CounterMode = TIM_COUNTERMODE_UP;
  htim4.Init.Period = 65535;
  htim4.Init.ClockDivision = TIM_CLOCKDIVISION_DIV1;
  htim4.Init.AutoReloadPreload = TIM_AUTORELOAD_PRELOAD_DISABLE;
  sConfig.EncoderMode = TIM_ENCODERMODE_TI12;
  sConfig.IC1Polarity = TIM_ICPOLARITY_RISING;
  sConfig.IC1Selection = TIM_ICSELECTION_DIRECTTI;
  sConfig.IC1Prescaler = TIM_ICPSC_DIV1;
  sConfig.IC1Filter = 0;
  sConfig.IC2Polarity = TIM_ICPOLARITY_RISING;
  sConfig.IC2Selection = TIM_ICSELECTION_DIRECTTI;
  sConfig.IC2Prescaler = TIM_ICPSC_DIV1;
  sConfig.IC2Filter = 0;
  if (HAL_TIM_Encoder_Init(&htim4, &sConfig) != HAL_OK)
  {
    Error_Handler();
  }
  sMasterConfig.MasterOutputTrigger = TIM_TRGO_RESET;
  sMasterConfig.MasterSlaveMode = TIM_MASTERSLAVEMODE_DISABLE;
  if (HAL_TIMEx_MasterConfigSynchronization(&htim4, &sMasterConfig) != HAL_OK)
  {
    Error_Handler();
  }

}

static void MX_TIM6_Init(void)
{

  TIM_MasterConfigTypeDef sMasterConfig = {0};

  htim6.Instance = TIM6;
  htim6.Init.Prescaler = 11;
  htim6.Init.CounterMode = TIM_COUNTERMODE_UP;
  htim6.Init.Period = 7499;
  htim6.Init.AutoReloadPreload = TIM_AUTORELOAD_PRELOAD_DISABLE;
  if (HAL_TIM_Base_Init(&htim6) != HAL_OK)
  {
    Error_Handler();
  }
  sMasterConfig.MasterOutputTrigger = TIM_TRGO_RESET;
  sMasterConfig.MasterSlaveMode = TIM_MASTERSLAVEMODE_DISABLE;
  if (HAL_TIMEx_MasterConfigSynchronization(&htim6, &sMasterConfig) != HAL_OK)
  {
    Error_Handler();
  }

}

static void MX_TIM7_Init(void)
{

  TIM_MasterConfigTypeDef sMasterConfig = {0};

  htim7.Instance = TIM7;
  htim7.Init.Prescaler = 11;
  htim7.Init.CounterMode = TIM_COUNTERMODE_UP;
  htim7.Init.Period = 749;
  htim7.Init.AutoReloadPreload = TIM_AUTORELOAD_PRELOAD_DISABLE;
  if (HAL_TIM_Base_Init(&htim7) != HAL_OK)
  {
    Error_Handler();
  }
  sMasterConfig.MasterOutputTrigger = TIM_TRGO_RESET;
  sMasterConfig.MasterSlaveMode = TIM_MASTERSLAVEMODE_DISABLE;
  if (HAL_TIMEx_MasterConfigSynchronization(&htim7, &sMasterConfig) != HAL_OK)
  {
    Error_Handler();
  }

}

static void MX_UART5_Init(void)
{

  huart5.Instance = UART5;
  huart5.Init.BaudRate = 115200;
  huart5.Init.WordLength = UART_WORDLENGTH_8B;
  huart5.Init.StopBits = UART_STOPBITS_1;
  huart5.Init.Parity = UART_PARITY_NONE;
  huart5.Init.Mode = UART_MODE_TX_RX;
  huart5.Init.HwFlowCtl = UART_HWCONTROL_NONE;
  huart5.Init.OverSampling = UART_OVERSAMPLING_16;
  if (HAL_UART_Init(&huart5) != HAL_OK)
  {
    Error_Handler();
  }

}

static void MX_DMA_Init(void)
{

  /* DMA controller clock enable */
  __HAL_RCC_DMA2_CLK_ENABLE();

  /* DMA interrupt init */
  /* DMA2_Stream0_IRQn interrupt configuration */
  HAL_NVIC_SetPriority(DMA2_Stream0_IRQn, 0, 0);
  HAL_NVIC_EnableIRQ(DMA2_Stream0_IRQn);

}

static void MX_GPIO_Init(void)
{
  GPIO_InitTypeDef GPIO_InitStruct = {0};

  /* GPIO Ports Clock Enable */
  __HAL_RCC_GPIOC_CLK_ENABLE();
  __HAL_RCC_GPIOH_CLK_ENABLE();
  __HAL_RCC_GPIOA_CLK_ENABLE();
  __HAL_RCC_GPIOB_CLK_ENABLE();
  __HAL_RCC_GPIOD_CLK_ENABLE();

  /*Configure GPIO pin Output Level */
  HAL_GPIO_WritePin(GPIOC, Output1_Pin|Output2_Pin, GPIO_PIN_RESET);

  /*Configure GPIO pin Output Level */
  HAL_GPIO_WritePin(GPIOB, CS_IMU_Pin|CS_MSD_Pin|LED_G_Pin|LED_B_Pin, GPIO_PIN_SET);

  /*Configure GPIO pin Output Level */
  HAL_GPIO_WritePin(LED_R_GPIO_Port, LED_R_Pin, GPIO_PIN_SET);

  /*Configure GPIO pins : Sidesensor1_Pin Input1_Pin SW_MSD_Pin */
  GPIO_InitStruct.Pin = Sidesensor1_Pin|Input1_Pin|SW_MSD_Pin;
  GPIO_InitStruct.Mode = GPIO_MODE_INPUT;
  GPIO_InitStruct.Pull = GPIO_PULLUP;
  HAL_GPIO_Init(GPIOC, &GPIO_InitStruct);

  /*Configure GPIO pins : Output1_Pin Output2_Pin */
  GPIO_InitStruct.Pin = Output1_Pin|Output2_Pin;
  GPIO_InitStruct.Mode = GPIO_MODE_OUTPUT_PP;
  GPIO_InitStruct.Pull = GPIO_PULLUP;
  GPIO_InitStruct.Speed = GPIO_SPEED_FREQ_LOW;
  HAL_GPIO_Init(GPIOC, &GPIO_InitStruct);

  /*Configure GPIO pin : Sidesensor2_Pin */
  GPIO_InitStruct.Pin = Sidesensor2_Pin;
  GPIO_InitStruct.Mode = GPIO_MODE_INPUT;
  GPIO_InitStruct.Pull = GPIO_PULLUP;
  HAL_GPIO_Init(Sidesensor2_GPIO_Port, &GPIO_InitStruct);

  /*Configure GPIO pin : Input2_Pin */
  GPIO_InitStruct.Pin = Input2_Pin;
  GPIO_InitStruct.Mode = GPIO_MODE_INPUT;
  GPIO_InitStruct.Pull = GPIO_NOPULL;
  HAL_GPIO_Init(Input2_GPIO_Port, &GPIO_InitStruct);

  /*Configure GPIO pins : CS_IMU_Pin CS_MSD_Pin LED_G_Pin LED_B_Pin */
  GPIO_InitStruct.Pin = CS_IMU_Pin|CS_MSD_Pin|LED_G_Pin|LED_B_Pin;
  GPIO_InitStruct.Mode = GPIO_MODE_OUTPUT_PP;
  GPIO_InitStruct.Pull = GPIO_PULLUP;
  GPIO_InitStruct.Speed = GPIO_SPEED_FREQ_LOW;
  HAL_GPIO_Init(GPIOB, &GPIO_InitStruct);

  /*Configure GPIO pin : LED_R_Pin */
  GPIO_InitStruct.Pin = LED_R_Pin;
  GPIO_InitStruct.Mode = GPIO_MODE_OUTPUT_PP;
  GPIO_InitStruct.Pull = GPIO_PULLUP;
  GPIO_InitStruct.Speed = GPIO_SPEED_FREQ_LOW;
  HAL_GPIO_Init(LED_R_GPIO_Port, &GPIO_InitStruct);

}

/* USER CODE BEGIN 4 */
void HAL_TIM_PeriodElapsedCallback(TIM_HandleTypeDef *htim)
{
    if(htim->Instance == TIM6){
      Interrupt1ms();
    }
    if(htim->Instance == TIM7){
      Interrupt100us();
      // cntRun++;
    }
}
// ADC interpput
void HAL_ADC_ConvCpltCallback(ADC_HandleTypeDef* AdcHandle) {
  getLineSensor();
}

// printf
int _write(int file, char *ptr, int len)
{
  int DataIdx;
  for(DataIdx=0; DataIdx<len; DataIdx++)
  {
    ITM_SendChar(*ptr++);
  }
  return len;
}
/* USER CODE END 4 */

void Error_Handler(void)
{
  __disable_irq();
  while (1)
  {
  }
}
